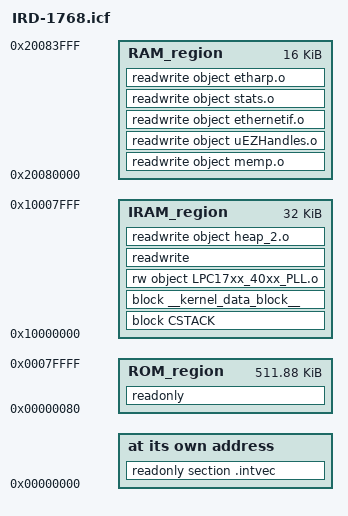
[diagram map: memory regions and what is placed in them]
/*###ICF### Section handled by ICF editor, don't touch! ****/
/*-Editor annotation file-*/
/* IcfEditorFile="$TOOLKIT_DIR$\config\ide\IcfEditor\a_v1_0.xml" */
/*-Specials-*/
define symbol __ICFEDIT_intvec_start__ = 0x00000000;
/*-Memory Regions-*/
define symbol __ICFEDIT_region_ROM_start__ = 0x00000080;
define symbol __ICFEDIT_region_ROM_end__   = 0x0007FFFF;
define symbol __ICFEDIT_region_RAM_start__ = 0x20080000;
define symbol __ICFEDIT_region_RAM_end__   = 0x20083FFF;
define symbol __ICFEDIT_region_IRAM_start__ = 0x10000000;
define symbol __ICFEDIT_region_IRAM_end__   = 0x10007FFF;
/*-Sizes-*/
define symbol __ICFEDIT_size_cstack__   = 0x200;

/**** End of ICF editor section. ###ICF###*/


/* This must match the number of implemented vectors * 4 and be padded to an 8
byte boundary (check the mapfile to ensure that the kernel function region is 
correctly occupying the first 8K region of flash). There does not seem to be any 
way of dynamically determining the size of the vector table section at link time, 
hence this direct definition. */
define symbol __size_vectors__              = 0xE8;

define memory mem with size = 4G;
define region ROM_region   = mem:[from __ICFEDIT_region_ROM_start__   to __ICFEDIT_region_ROM_end__];
define region RAM_region   = mem:[from __ICFEDIT_region_RAM_start__   to __ICFEDIT_region_RAM_end__];
define region IRAM_region   = mem:[from __ICFEDIT_region_IRAM_start__   to __ICFEDIT_region_IRAM_end__];


define block CSTACK    with alignment = 8, size = __ICFEDIT_size_cstack__   { };

initialize by copy { readwrite };
do not initialize  { section .noinit };

/* Place the interrupt vectors at the required address, followed by the kernel's
functions. */
place at address mem:__ICFEDIT_intvec_start__ { readonly section .intvec };

/* Define a block for the kernel's data. */
define block __kernel_data_block__ with alignment = 0x400, size = 0x400 { section __kernel_data__ };

/* Place the main stack at the start of IRAM, followed by the kernel's data. */
place in IRAM_region { 
    block CSTACK, 
    block __kernel_data_block__, 
    rw object LPC17xx_40xx_PLL.o, 
    readwrite,
    readwrite object heap_2.o
    };

place in ROM_region   { readonly };
place in RAM_region   { 
    readwrite object memp.o, 
    readwrite object uEZHandles.o,
    readwrite object ethernetif.o,
    readwrite object stats.o,
    readwrite object etharp.o
};
                        
/* Export symbols required by c code. */
export symbol __ICFEDIT_intvec_start__;
export symbol __ICFEDIT_size_cstack__;
export symbol __ICFEDIT_region_ROM_start__;
export symbol __ICFEDIT_region_ROM_end__;       
